# CY8C5888LTI_LP097 register map
File version: 0.1
CY8C58LP
Registers are 8-bit, read-write, no defined reset value unless marked. A register's access mark holds for its fields unless they carry their own. Offsets are from the block's base; lines under a group give offsets from that group; [hi:lo] are bit positions; {n}, {i} and the like mark numbered series; 'fields as' and 'values as' point back to an identical list; <NAME> marks a mode.

## Memory map
0x00000000 UART

## UART
Base 0x00000000
0x40006449 TX_UART_TX_DATA — TX Data Register
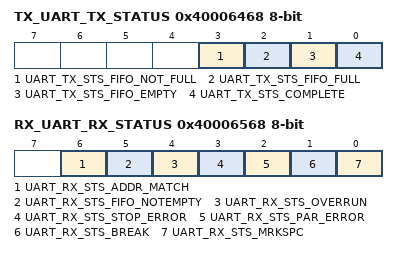
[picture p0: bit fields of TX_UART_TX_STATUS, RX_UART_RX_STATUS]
0x40006468 TX_UART_TX_STATUS — TX status register
  [3] UART_TX_STS_FIFO_NOT_FULL ro, [2] UART_TX_STS_FIFO_FULL ro, [1] UART_TX_STS_FIFO_EMPTY ro, [0] UART_TX_STS_COMPLETE ro
0x40006528 RX_UART_RX_ADDRESS1 — RX Address1 Register
0x40006538 RX_UART_RX_ADDRESS2 — RX Address2 Register
0x40006548 RX_UART_RX_DATA — RX Data Register
0x40006568 RX_UART_RX_STATUS — RX status register
  [6] UART_RX_STS_ADDR_MATCH ro, [5] UART_RX_STS_FIFO_NOTEMPTY ro, [4] UART_RX_STS_OVERRUN ro, [3] UART_RX_STS_STOP_ERROR ro, [2] UART_RX_STS_PAR_ERROR ro, [1] UART_RX_STS_BREAK ro, [0] UART_RX_STS_MRKSPC ro
